AUTOSAR XML (schema 4-3-0)
package /Example
  client server interface MyInterface1
  application sw component type Planner
    provide port PortPlanner: provided-interface=SensorFusion
package /p1
  sender receiver interface SensorFusion
  client server interface ActuatorControl
package /p1/p2/p3
  sender receiver interface Sr
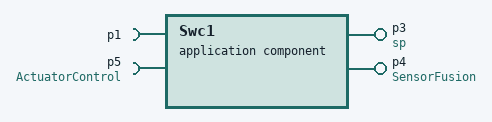
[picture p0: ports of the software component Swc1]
  application sw component type Swc1
    require port p1
    provide port p3: provided-interface=sp
    provide port p4: provided-interface=SensorFusion
    require port p5: required-interface=ActuatorControl
  client server interface sp
